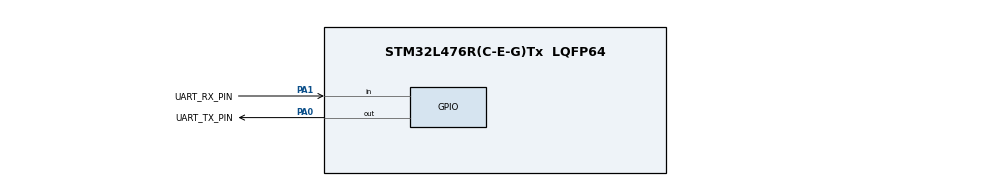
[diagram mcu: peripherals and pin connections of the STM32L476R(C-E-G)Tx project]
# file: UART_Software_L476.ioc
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Mcu.Family=STM32L4
Mcu.Name=STM32L476R(C-E-G)Tx
Mcu.Package=LQFP64
NVIC.PriorityGroup=NVIC_PRIORITYGROUP_4
PA0.GPIO_Label=UART_TX_PIN
PA0.GPIO_PuPd=GPIO_NOPULL
PA0.GPIO_Speed=GPIO_SPEED_FREQ_VERY_HIGH
PA0.Signal=GPIO_Output
PA1.GPIO_Label=UART_RX_PIN
PA1.GPIO_PuPd=GPIO_PULLUP
PA1.Signal=GPIO_Input
ProjectManager.HeapSize=0x200
ProjectManager.StackSize=0x400
ProjectManager.TargetToolchain=MDK-ARM V5.32
RCC.AHBFreq_Value=40000000
RCC.APB1Freq_Value=40000000
RCC.APB1TimFreq_Value=40000000
RCC.APB2Freq_Value=40000000
RCC.APB2TimFreq_Value=40000000
RCC.CortexFreq_Value=40000000
RCC.HCLKFreq_Value=40000000
RCC.HSE_VALUE=8000000
RCC.HSI_VALUE=16000000
RCC.LSE_VALUE=32768
RCC.MSI_VALUE=4000000
RCC.PLLN=20
RCC.SYSCLKFreq_VALUE=40000000
RCC.SYSCLKSource=RCC_SYSCLKSOURCE_PLLCLK
RCC.VCOOutputFreq_Value=80000000
TIM2.Period=9
TIM2.Prescaler=3
VP_TIM2_VS_ClockSourceINT.Mode=Internal
board=custom

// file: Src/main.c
/* USER CODE BEGIN Header */
/**
  ******************************************************************************
  * @file           : main.c
  * @brief          : Main program body
  ******************************************************************************
  * @attention
  *
  * Copyright (c) 2024 STMicroelectronics.
  * All rights reserved.
  *
  * This software is licensed under terms that can be found in the LICENSE file
  * in the root directory of this software component.
  * If no LICENSE file comes with this software, it is provided AS-IS.
  *
  ******************************************************************************
  */
/* USER CODE END Header */
#include "main.h"

/* USER CODE BEGIN PD */
#define UART_TX_PIN        LL_GPIO_PIN_0
#define UART_RX_PIN        LL_GPIO_PIN_1
#define UART_GPIO_PORT     GPIOA
#define BAUD_RATE_DELAY    104 // Delay cho baud 9600 là khoang 104 µs
/* USER CODE END PD */

/* USER CODE BEGIN PV */
uint8_t receivedChar;

/* USER CODE END PV */

void SystemClock_Config(void);
static void MX_GPIO_Init(void);
static void MX_TIM2_Init(void);
/* USER CODE BEGIN PFP */
void delay_us(uint32_t delay);
void UARTSoftware_Init(void);
uint8_t UART_ReceiveChar(void);
void UART_SendChar(uint8_t ch);
/* USER CODE END PFP */

int main(void)
{

  /* MCU Configuration--------------------------------------------------------*/

  /* Reset of all peripherals, Initializes the Flash interface and the Systick. */
  LL_APB2_GRP1_EnableClock(LL_APB2_GRP1_PERIPH_SYSCFG);
  LL_APB1_GRP1_EnableClock(LL_APB1_GRP1_PERIPH_PWR);

  /* System interrupt init*/
  //NVIC_SetPriorityGrouping(NVIC_PRIORITYGROUP_4);

  /* SysTick_IRQn interrupt configuration */
  //NVIC_SetPriority(SysTick_IRQn, NVIC_EncodePriority(NVIC_GetPriorityGrouping(),15, 0));

  /* Configure the system clock */
  SystemClock_Config();

  /* Initialize all configured peripherals */
  MX_GPIO_Init();
  MX_TIM2_Init();
  /* USER CODE BEGIN 2 */
	UARTSoftware_Init();
  /* USER CODE END 2 */

  /* Infinite loop */
  while (1)
  {

    /* USER CODE BEGIN 3 */
		uint8_t sendchar = 'c';
		receivedChar = UART_ReceiveChar(); // Nh?n ký t? t? RX
    UART_SendChar(sendchar);       // G?i l?i ký t? qua TX
  }
  /* USER CODE END 3 */
}

void SystemClock_Config(void)
{
  LL_FLASH_SetLatency(LL_FLASH_LATENCY_2);
  while(LL_FLASH_GetLatency()!= LL_FLASH_LATENCY_2)
  {
  }
  LL_PWR_SetRegulVoltageScaling(LL_PWR_REGU_VOLTAGE_SCALE1);
  while (LL_PWR_IsActiveFlag_VOS() != 0)
  {
  }
  LL_RCC_MSI_Enable();

   /* Wait till MSI is ready */
  while(LL_RCC_MSI_IsReady() != 1)
  {

  }
  LL_RCC_MSI_EnableRangeSelection();
  LL_RCC_MSI_SetRange(LL_RCC_MSIRANGE_6);
  LL_RCC_MSI_SetCalibTrimming(0);
  LL_RCC_PLL_ConfigDomain_SYS(LL_RCC_PLLSOURCE_MSI, LL_RCC_PLLM_DIV_1, 20, LL_RCC_PLLR_DIV_2);
  LL_RCC_PLL_EnableDomain_SYS();
  LL_RCC_PLL_Enable();

   /* Wait till PLL is ready */
  while(LL_RCC_PLL_IsReady() != 1)
  {

  }
  LL_RCC_SetSysClkSource(LL_RCC_SYS_CLKSOURCE_PLL);

   /* Wait till System clock is ready */
  while(LL_RCC_GetSysClkSource() != LL_RCC_SYS_CLKSOURCE_STATUS_PLL)
  {

  }
  LL_RCC_SetAHBPrescaler(LL_RCC_SYSCLK_DIV_1);
  LL_RCC_SetAPB1Prescaler(LL_RCC_APB1_DIV_1);
  LL_RCC_SetAPB2Prescaler(LL_RCC_APB2_DIV_1);

  LL_Init1msTick(40000000);

  LL_SetSystemCoreClock(40000000);
}

static void MX_TIM2_Init(void)
{

  LL_TIM_InitTypeDef TIM_InitStruct = {0};

  /* Peripheral clock enable */
  LL_APB1_GRP1_EnableClock(LL_APB1_GRP1_PERIPH_TIM2);

  TIM_InitStruct.Prescaler = 3;
  TIM_InitStruct.CounterMode = LL_TIM_COUNTERMODE_UP;
  TIM_InitStruct.Autoreload = 9;
  TIM_InitStruct.ClockDivision = LL_TIM_CLOCKDIVISION_DIV1;
  LL_TIM_Init(TIM2, &TIM_InitStruct);
  LL_TIM_DisableARRPreload(TIM2);
  LL_TIM_SetClockSource(TIM2, LL_TIM_CLOCKSOURCE_INTERNAL);
  LL_TIM_SetTriggerOutput(TIM2, LL_TIM_TRGO_RESET);
  LL_TIM_DisableMasterSlaveMode(TIM2);
  /* USER CODE BEGIN TIM2_Init 2 */
	LL_TIM_EnableCounter(TIM2);
  /* USER CODE END TIM2_Init 2 */

}

static void MX_GPIO_Init(void)
{
  LL_GPIO_InitTypeDef GPIO_InitStruct = {0};

  /* GPIO Ports Clock Enable */
  LL_AHB2_GRP1_EnableClock(LL_AHB2_GRP1_PERIPH_GPIOA);

  /**/
  LL_GPIO_ResetOutputPin(UART_TX_PIN_GPIO_Port, UART_TX_PIN_Pin);

  /**/
  GPIO_InitStruct.Pin = UART_TX_PIN_Pin;
  GPIO_InitStruct.Mode = LL_GPIO_MODE_OUTPUT;
  GPIO_InitStruct.Speed = LL_GPIO_SPEED_FREQ_VERY_HIGH;
  GPIO_InitStruct.OutputType = LL_GPIO_OUTPUT_PUSHPULL;
  GPIO_InitStruct.Pull = LL_GPIO_PULL_NO;
  LL_GPIO_Init(UART_TX_PIN_GPIO_Port, &GPIO_InitStruct);

  /**/
  GPIO_InitStruct.Pin = UART_RX_PIN_Pin;
  GPIO_InitStruct.Mode = LL_GPIO_MODE_INPUT;
  GPIO_InitStruct.Pull = LL_GPIO_PULL_NO;
  LL_GPIO_Init(UART_RX_PIN_GPIO_Port, &GPIO_InitStruct);

}

/* USER CODE BEGIN 4 */
void delay_us(uint32_t timeDelay)
{
    for (uint32_t i = 0; i < timeDelay; i++)
    {
        LL_TIM_SetCounter(TIM2, 0);
			  LL_TIM_EnableCounter(TIM2);
        while (!LL_TIM_IsActiveFlag_UPDATE(TIM2));
        LL_TIM_ClearFlag_UPDATE(TIM2);
    }
}
void UARTSoftware_Init(void)
{
	LL_GPIO_SetOutputPin(UART_GPIO_PORT, UART_TX_PIN);
	delay_us(1);
}

void UART_SendChar(uint8_t ch)
{
    // G?i Start Bit (th?p)
    LL_GPIO_ResetOutputPin(UART_GPIO_PORT, UART_TX_PIN);
    delay_us(BAUD_RATE_DELAY);

    // G?i t?ng bit (LSB tru?c)
    for (uint8_t i = 0; i < 8; i++)
    {
        if ((ch >> i) & 0x01)
        {
            LL_GPIO_SetOutputPin(UART_GPIO_PORT, UART_TX_PIN); // Bit 1
        }
        else
        {
            LL_GPIO_ResetOutputPin(UART_GPIO_PORT, UART_TX_PIN); // Bit 0
        }
        delay_us(BAUD_RATE_DELAY);
    }

    // G?i Stop Bit (cao)
    LL_GPIO_SetOutputPin(UART_GPIO_PORT, UART_TX_PIN);
    delay_us(BAUD_RATE_DELAY);
}

uint8_t UART_ReceiveChar(void)
{
    char receivedChar = 0;

    // Ch? Start Bit
    while (LL_GPIO_IsInputPinSet(UART_GPIO_PORT, UART_RX_PIN));

    // Delay d? vào gi?a Start Bit
    delay_us(BAUD_RATE_DELAY / 2);

    // Ð?c t?ng bit (LSB tru?c)
    for (uint8_t i = 0; i < 8; i++)
    {
        delay_us(BAUD_RATE_DELAY); // Delay gi?a các bit
        if (LL_GPIO_IsInputPinSet(UART_GPIO_PORT, UART_RX_PIN))
        {
            receivedChar |= (1 << i); // Set bit n?u RX ? m?c cao
        }
    }

    // Ch? Stop Bit
    delay_us(BAUD_RATE_DELAY);

    return receivedChar;
}
/* USER CODE END 4 */

void Error_Handler(void)
{
  __disable_irq();
  while (1)
  {
  }
}
